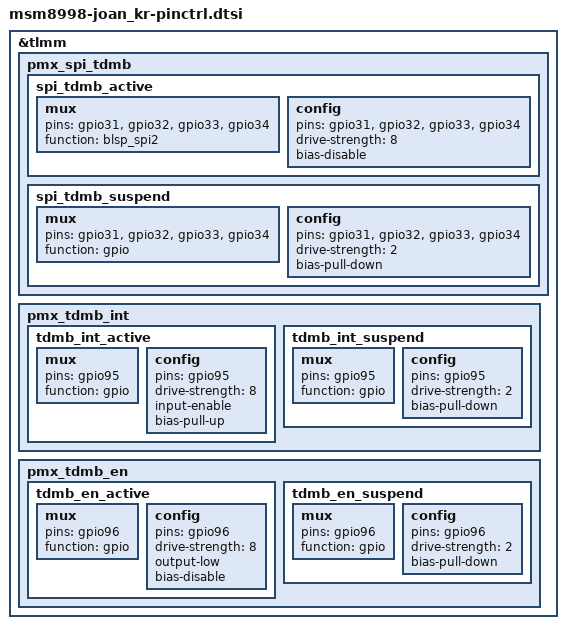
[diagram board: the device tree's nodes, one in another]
/* Copyright (c) 2015-2016, The Linux Foundation. All rights reserved.
 *
 * This program is free software; you can redistribute it and/or modify
 * it under the terms of the GNU General Public License version 2 and
 * only version 2 as published by the Free Software Foundation.
 *
 * This program is distributed in the hope that it will be useful,
 * but WITHOUT ANY WARRANTY; without even the implied warranty of
 * MERCHANTABILITY or FITNESS FOR A PARTICULAR PURPOSE.  See the
 * GNU General Public License for more details.
 */

#include "../msm8998-joan-common/msm8998-joan-common-pinctrl.dtsi"

&tlmm {
	pmx_spi_tdmb {
		spi_tdmb_active: spi_tdmb_active {
			mux {
				pins =  "gpio31", "gpio32", "gpio33", "gpio34";
				function = "blsp_spi2";
			};

			config {
				pins =  "gpio31", "gpio32", "gpio33", "gpio34";
				drive-strength = <8>;
				bias-disable;
			};
		};

		spi_tdmb_suspend: spi_tdmb_suspend {
			mux {
				pins =  "gpio31", "gpio32", "gpio33", "gpio34";
				function = "gpio";
			};

			config {
				pins =  "gpio31", "gpio32", "gpio33", "gpio34";
				drive-strength = <2>;
				bias-pull-down;
			};
		};
	};

	pmx_tdmb_int {
		tdmb_int_active: tdmb_int_active {
			mux {
				pins = "gpio95";
				function = "gpio";
			};
			config {
				pins = "gpio95";
				drive-strength = <8>;
				input-enable;
				bias-pull-up;
			};
		};
		tdmb_int_suspend: tdmb_int_suspend {
			mux {
				pins = "gpio95";
				function = "gpio";
			};
			config {
				pins = "gpio95";
				drive-strength = <2>;
				bias-pull-down;
			};
		};
	};

	pmx_tdmb_en {
		tdmb_en_active: tdmb_en_active {
			mux {
				pins = "gpio96";
				function = "gpio";
			};
			config {
				pins = "gpio96";
				drive-strength = <8>;
				output-low;
				bias-disable;
			};
		};

		tdmb_en_suspend: tdmb_en_suspend {
			mux {
				pins = "gpio96";
				function = "gpio";
			};
			config {
				pins = "gpio96";
				drive-strength = <2>;
				bias-pull-down;
			};
		};
	};
};
